VERSION ""

NS_ :

BS_:

BU_: VCU NCU

BO_ 2566888945 NCU_EHC: 8 NCU
 SG_ Remote_Control_Enable : 48|2@1+ (1,0) [0|0] ""  VCU
 SG_ Rocker_Switch : 40|4@1+ (1,0) [0|0] ""  VCU

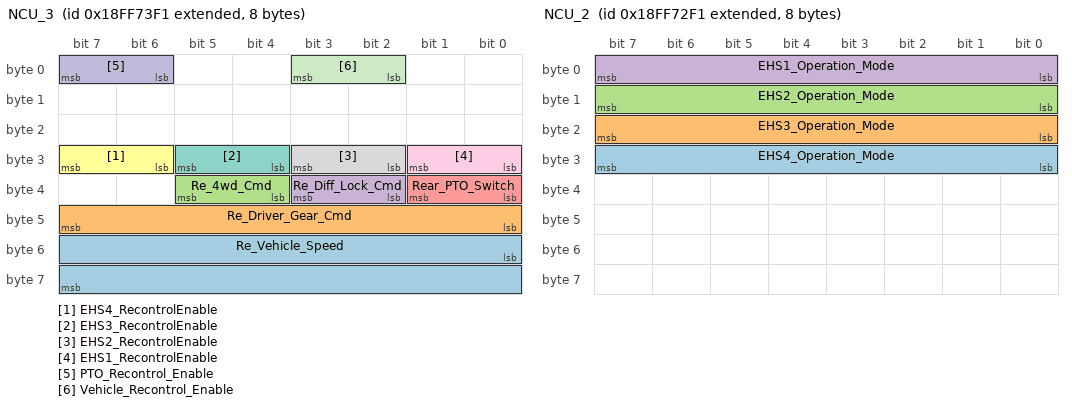
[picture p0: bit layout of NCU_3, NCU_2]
BO_ 2566878193 NCU_3: 8 NCU
 SG_ Re_Vehicle_Speed : 48|16@1+ (0.003906,0) [0|0] ""  VCU
 SG_ Re_Driver_Gear_Cmd : 40|8@1+ (1,0) [0|0] ""  VCU
 SG_ Re_4wd_Cmd : 36|2@1+ (1,0) [0|0] ""  VCU
 SG_ Re_Diff_Lock_Cmd : 34|2@1+ (1,0) [0|0] ""  VCU
 SG_ Rear_PTO_Switch : 32|2@1+ (1,0) [0|0] ""  VCU
 SG_ EHS4_RecontrolEnable : 30|2@1+ (1,0) [0|0] ""  VCU
 SG_ EHS3_RecontrolEnable : 28|2@1+ (1,0) [0|0] ""  VCU
 SG_ EHS2_RecontrolEnable : 26|2@1+ (1,0) [0|0] ""  VCU
 SG_ EHS1_RecontrolEnable : 24|2@1+ (1,0) [0|0] ""  VCU
 SG_ PTO_Recontrol_Enable : 6|2@1+ (1,0) [0|0] ""  VCU
 SG_ Vehicle_Recontrol_Enable : 2|2@1+ (1,0) [0|0] ""  VCU

BO_ 2566877937 NCU_2: 8 NCU
 SG_ EHS4_Operation_Mode : 24|8@1+ (1,0) [0|0] ""  VCU
 SG_ EHS3_Operation_Mode : 16|8@1+ (1,0) [0|0] ""  VCU
 SG_ EHS2_Operation_Mode : 8|8@1+ (1,0) [0|0] ""  VCU
 SG_ EHS1_Operation_Mode : 0|8@1+ (1,0) [0|0] ""  VCU

BO_ 2566877681 NCU_1: 8 NCU
 SG_ Front_Steer_Angle_Cmd : 8|16@1+ (0.01,-100) [0|0] ""  VCU
 SG_ Automatic_Driver_Enable : 0|2@1+ (1,0) [0|0] ""  VCU

BO_ 2566904560 VCU_3: 8 VCU
 SG_ Front_Steer_Angle : 16|16@1+ (0.01,-100) [0|0] ""  NCU

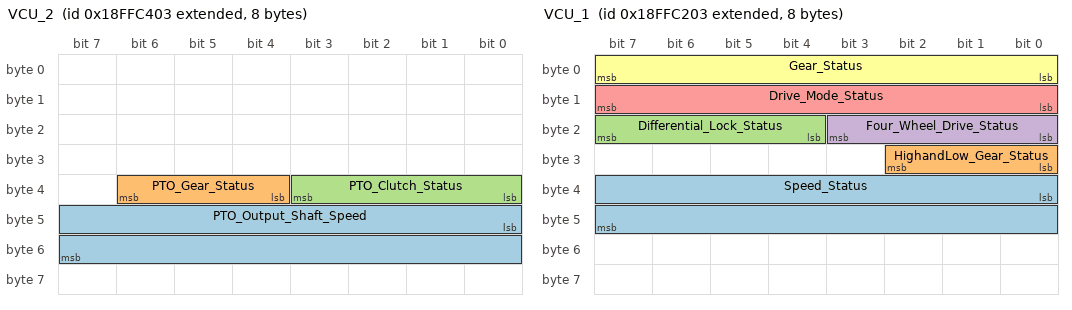
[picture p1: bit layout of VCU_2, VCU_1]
BO_ 2566898691 VCU_2: 8 VCU
 SG_ PTO_Output_Shaft_Speed : 40|16@1+ (0.125,0) [0|0] ""  NCU
 SG_ PTO_Gear_Status : 36|3@1+ (1,0) [0|0] ""  NCU
 SG_ PTO_Clutch_Status : 32|4@1+ (1,0) [0|0] ""  NCU

BO_ 2566898179 VCU_1: 8 VCU
 SG_ Speed_Status : 32|16@1+ (0.003096,0) [0|0] ""  NCU
 SG_ HighandLow_Gear_Status : 24|3@1+ (1,0) [0|0] ""  NCU
 SG_ Differential_Lock_Status : 20|4@1+ (1,0) [0|0] ""  NCU
 SG_ Four_Wheel_Drive_Status : 16|4@1+ (1,0) [0|0] ""  NCU
 SG_ Drive_Mode_Status : 8|8@1+ (1,0) [0|0] ""  NCU
 SG_ Gear_Status : 0|8@1+ (1,0) [0|0] ""  NCU
